# M4K4A register map
File version: 0.1
TOSHIBA Cortex-M4 MCU
Registers are 32-bit, read-write, reset 0x0 unless marked. A register's access mark holds for its fields unless they carry their own. Offsets are from the block's base; lines under a group give offsets from that group; [hi:lo] are bit positions; {n}, {i} and the like mark numbered series; 'fields as' and 'values as' point back to an identical list; <NAME> marks a mode.

## Memory map
0x4003E000 IA blocks up to offset 0x44 — Interrupt control A Register
0x4003E400 RLM blocks up to offset 0x4 — Reset LOSC_Low power_ Management register
0x4003EC00 LVD size 0x1 — LVD0
0x4004C000 DMA blocks up to offset 0x50 — DMA Controller
0x40098000 TSPI0 blocks up to offset 0x208 — Serial Interface (TSPI)
0x40099000 TSPI1 blocks up to offset 0x208
0x4009A000 TSPI2 blocks up to offset 0x208
0x4009B000 TSPI3 blocks up to offset 0x208
0x400A0000 I2C size 0x28
0x400B8700 SH blocks up to offset 0x10 — Sampl-and-hold circuit
0x400B8800 AD blocks up to offset 0x1D0 — 12-bit ADC
0x400BA000 T32A0 blocks up to offset 0xFC — T32A
0x400BA100 T32A1 blocks up to offset 0xFC
0x400BA200 T32A2 blocks up to offset 0xFC
0x400BA300 T32A3 blocks up to offset 0xFC
0x400BA400 T32A4 blocks up to offset 0xFC
0x400BA500 T32A5 blocks up to offset 0xFC
0x400BB000 UART0 size 0x28 — UART
0x400BB100 UART1 size 0x28
0x400BB200 UART2 size 0x28
0x400BB300 UART3 size 0x28
0x400BB400 SIWD size 0x18
0x400BB600 DNF size 0x8
0x400BB800 TSEL size 0x2C — TRGSEL
0x400BBA00 NBD size 0x8
0x400BBB00 RPAR size 0x18 — RAM Parity
0x400BBC00 CRC blocks up to offset 0x30
0x400BC000 AMP size 0xC
0x400C0000 PA blocks up to offset 0x3C — Port A
0x400C0100 PB blocks up to offset 0x3C — Port B
0x400C0200 PC blocks up to offset 0x3C — Port C
0x400C0300 PD blocks up to offset 0x3C — Port D
0x400C0400 PE blocks up to offset 0x3C — Port E
0x400C0500 PF blocks up to offset 0x3C
0x400C0600 PG blocks up to offset 0x3C
0x400C0700 PH blocks up to offset 0x3C
0x400C0800 PJ blocks up to offset 0x3C
0x400C0900 PK blocks up to offset 0x3C
0x400C0A00 PL blocks up to offset 0x3C
0x400F1000 OFD size 0x24
0x400F3000 CG blocks up to offset 0x60
0x400F3200 TRM size 0x10 — TRIM
0x400F4E00 IB blocks up to offset 0x89 — Interrupt control register B
0x400F4F00 IMN size 0x14 — Interrupt Monitor Register
0x400F6000 PMD0 size 0x7C — A-PMD
0x400F6100 PMD1 size 0x7C
0x400F7000 EN size 0x34 — Encoder Input (ENC)
0x400F8000 VE blocks up to offset 0x248
0x5DFF0000 FC blocks up to offset 0x15C

## IA — Interrupt control A Register
Base 0x4003E000
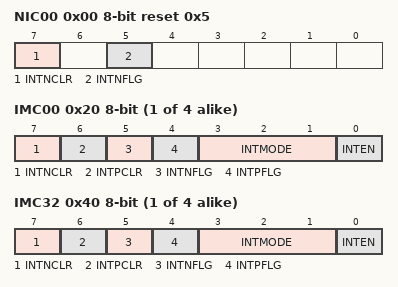
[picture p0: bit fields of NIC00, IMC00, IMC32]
0x00 NIC00 8-bit reset 0x5 — Non makeable Interrupt Control(A) 00
  [7] INTNCLR wo, [5] INTNFLG ro
{0x20+i} IMC{i:02} 8-bit (i=0..3) — Interrupu Mode Control Register(A) {i:02}
  [7] INTNCLR wo, [6] INTPCLR wo, [5] INTNFLG ro, [4] INTPFLG ro, [3:1] INTMODE, [0] INTEN
{0x20+i} IMC{i} 8-bit (i=32..35) — Interrupu Mode Control Register(A) {i}
  fields as IMC00

## RLM — Reset LOSC_Low power_ Management register
Base 0x4003E400
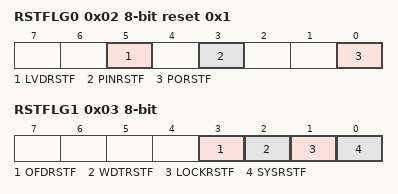
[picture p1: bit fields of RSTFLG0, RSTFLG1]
0x02 RSTFLG0 8-bit reset 0x1 (reset mask 0x1) — Reset flag register 0
  [5] LVDRSTF, [3] PINRSTF, [0] PORSTF
0x03 RSTFLG1 8-bit — Reset flag register 1
  [3] OFDRSTF, [2] WDTRSTF, [1] LOCKRSTF, [0] SYSRSTF

## LVD — LVD0
Base 0x4003EC00
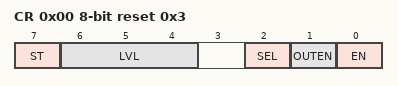
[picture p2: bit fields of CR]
0x00 CR 8-bit reset 0x3 — LVD Control register
  [7] ST ro, [6:4] LVL, [2] SEL, [1] OUTEN, [0] EN

## DMA — DMA Controller
Base 0x4004C000
0x00 STATUS ro reset 0x101F0000 — DMA Status Register
  [0] MASTER_ENABLE
0x04 CFG wo — DMA Configuration Register
  [0] MASTER_ENABLE
0x08 CTRLBASEPTR — DMA Control Data Base Pointer Register
  [31:10] CTRL_BASE_PTR
0x0C ALTCTRLBASEPTR ro — DMA Channel Alternate Control Data Base Pointer Register
  [31:0] ALT_CTRL_BASE_PTR
0x14 CHNLSWREQUEST wo — DMA Channel Software Request Register
  [31:0] CHNL_SW_REQUEST
0x18 CHNLUSEBURSTSET — DMA Channel Useburst Set Register
  [31:0] CHNL_USEBURST_SET
0x1C CHNLUSEBURSTCLR wo — DMA Channel Useburst Clear Register
  [31:0] CHNL_USEBURST_CLR
0x20 CHNLREQMASKSET — DMA Channel Request Mask Set Register
  [31:0] CHNL_REQ_MASK_SET
0x24 CHNLREQMASKCLR wo — DMA Channel Request Mask Clear Register
  [31:0] CHNL_REQ_MASK_CLR
0x28 CHNLENABLESET — DMA Channel Enable Set Register
  [31:0] CHNL_ENABLE_SET
0x2C CHNLENABLECLR wo — DMA Channel Enable Clear Register
  [31:0] CHNL_ENABLE_CLR
0x30 CHNLPRIALTSET — DMA Channel Primary-Alternate Set Register
  [31:0] CHNL_PRI_ALT_SET
0x34 CHNLPRIALTCLR wo — DMA Channel Primary-Alternate Clear Register
  [31:0] CHNL_PRI_ALT_CLR
0x38 CHNLPRIORITYSET — DMA Channel Priority Set Register
  [31:0] CHNL_PRIORITY_SET
0x3C CHNLPRIORITYCLR wo — DMA Channel Priority Clear Register
  [31:0] CHNL_PRIORITY_CLR
0x4C ERRCLR — DMA Bus Error Clear Register
  [0] ERR_CLR
